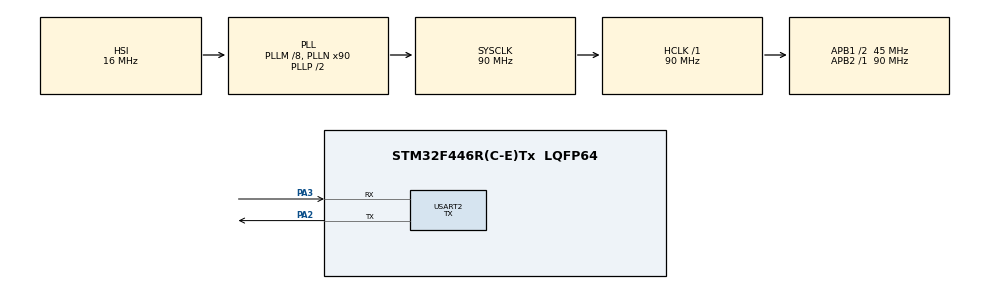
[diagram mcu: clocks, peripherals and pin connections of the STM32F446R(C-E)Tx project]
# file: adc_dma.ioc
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ADC1.Channel-0\#ChannelRegularConversion=ADC_CHANNEL_TEMPSENSOR
ADC1.ContinuousConvMode=ENABLE
ADC1.DMAContinuousRequests=DISABLE
ADC1.NbrOfConversion=1
ADC1.NbrOfConversionFlag=1
ADC1.Rank-0\#ChannelRegularConversion=1
ADC1.Resolution=ADC_RESOLUTION_8B
ADC1.SamplingTime-0\#ChannelRegularConversion=ADC_SAMPLETIME_480CYCLES
ADC1.master=1
Mcu.Family=STM32F4
Mcu.Name=STM32F446R(C-E)Tx
Mcu.Package=LQFP64
NVIC.ADC_IRQn=true\:0\:0\:false\:false\:true\:true\:true
NVIC.FPU_IRQn=true\:0\:0\:false\:false\:true\:true\:false
NVIC.PriorityGroup=NVIC_PRIORITYGROUP_4
NVIC.RCC_IRQn=true\:0\:0\:false\:false\:true\:true\:false
PA2.Mode=Asynchronous
PA2.Signal=USART2_TX
PA3.Mode=Asynchronous
PA3.Signal=USART2_RX
ProjectManager.HeapSize=0x200
ProjectManager.StackSize=0x400
ProjectManager.TargetToolchain=SW4STM32
RCC.AHBFreq_Value=90000000
RCC.APB1CLKDivider=RCC_HCLK_DIV2
RCC.APB1Freq_Value=45000000
RCC.APB1TimFreq_Value=90000000
RCC.APB2Freq_Value=90000000
RCC.APB2TimFreq_Value=90000000
RCC.CortexFreq_Value=90000000
RCC.HCLKFreq_Value=90000000
RCC.PLLM=8
RCC.PLLN=90
RCC.SYSCLKFreq_VALUE=90000000
RCC.SYSCLKSource=RCC_SYSCLKSOURCE_PLLCLK
RCC.USBFreq_Value=90000000
RCC.VCOOutputFreq_Value=180000000
USART2.Mode=MODE_TX
USART2.OverSampling=UART_OVERSAMPLING_8
USART2.VirtualMode=VM_ASYNC
VP_ADC1_TempSens_Input.Mode=IN-TempSens
board=custom

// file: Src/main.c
/* USER CODE BEGIN Header */
/**
  ******************************************************************************
  * @file           : main.c
  * @brief          : Main program body
  ******************************************************************************
  * @attention
  *
  * <h2><center>&copy; Copyright (c) 2019 STMicroelectronics.
  * All rights reserved.</center></h2>
  *
  * This software component is licensed by ST under BSD 3-Clause license,
  * the "License"; You may not use this file except in compliance with the
  * License. You may obtain a copy of the License at:
  *                        opensource.org/licenses/BSD-3-Clause
  *
  ******************************************************************************
  */
/* USER CODE END Header */

#include "main.h"

/* USER CODE BEGIN PD */

#ifdef __GNUC__
/* With GCC/RAISONANCE, small printf (option LD Linker->Libraries->Small printf
 set to 'Yes') calls __io_putchar() */
#define PUTCHAR_PROTOTYPE int __io_putchar(int ch)
#endif

/* USER CODE END PD */

ADC_HandleTypeDef hadc1;

UART_HandleTypeDef huart2;

/* USER CODE BEGIN PV */
uint16_t PomiarADC;
float Temperature;
float Vsense;

/* USER CODE END PV */

void SystemClock_Config(void);
static void MX_GPIO_Init(void);
static void MX_ADC1_Init(void);
static void MX_USART2_UART_Init(void);

/* USER CODE BEGIN 0 */
	const float V25 = 0.76; // [Volts]
	const float Avg_slope = 0.0025; //[Volts/degree]
	const float SupplyVoltage = 3.0; // [Volts]
	const float ADCResolution = 255.0;

/* USER CODE END 0 */

int main(void)
{

  /* MCU Configuration--------------------------------------------------------*/

  /* Reset of all peripherals, Initializes the Flash interface and the Systick. */
  HAL_Init();

  /* Configure the system clock */
  SystemClock_Config();

  /* Initialize all configured peripherals */
  MX_GPIO_Init();
  MX_ADC1_Init();
  MX_USART2_UART_Init();
  /* USER CODE BEGIN 2 */
  __enable_irq();
  printf("hello!\r\n");

  HAL_ADC_Start_IT(&hadc1);

  /* USER CODE END 2 */

  /* Infinite loop */
  while (1)
  {

  }
}

void SystemClock_Config(void)
{
  RCC_OscInitTypeDef RCC_OscInitStruct = {0};
  RCC_ClkInitTypeDef RCC_ClkInitStruct = {0};

  /** Configure the main internal regulator output voltage
  */
  __HAL_RCC_PWR_CLK_ENABLE();
  __HAL_PWR_VOLTAGESCALING_CONFIG(PWR_REGULATOR_VOLTAGE_SCALE3);
  /** Initializes the CPU, AHB and APB busses clocks
  */
  RCC_OscInitStruct.OscillatorType = RCC_OSCILLATORTYPE_HSI;
  RCC_OscInitStruct.HSIState = RCC_HSI_ON;
  RCC_OscInitStruct.HSICalibrationValue = RCC_HSICALIBRATION_DEFAULT;
  RCC_OscInitStruct.PLL.PLLState = RCC_PLL_ON;
  RCC_OscInitStruct.PLL.PLLSource = RCC_PLLSOURCE_HSI;
  RCC_OscInitStruct.PLL.PLLM = 8;
  RCC_OscInitStruct.PLL.PLLN = 90;
  RCC_OscInitStruct.PLL.PLLP = RCC_PLLP_DIV2;
  RCC_OscInitStruct.PLL.PLLQ = 2;
  RCC_OscInitStruct.PLL.PLLR = 2;
  if (HAL_RCC_OscConfig(&RCC_OscInitStruct) != HAL_OK)
  {
    Error_Handler();
  }
  /** Initializes the CPU, AHB and APB busses clocks
  */
  RCC_ClkInitStruct.ClockType = RCC_CLOCKTYPE_HCLK|RCC_CLOCKTYPE_SYSCLK
                              |RCC_CLOCKTYPE_PCLK1|RCC_CLOCKTYPE_PCLK2;
  RCC_ClkInitStruct.SYSCLKSource = RCC_SYSCLKSOURCE_PLLCLK;
  RCC_ClkInitStruct.AHBCLKDivider = RCC_SYSCLK_DIV1;
  RCC_ClkInitStruct.APB1CLKDivider = RCC_HCLK_DIV2;
  RCC_ClkInitStruct.APB2CLKDivider = RCC_HCLK_DIV1;

  if (HAL_RCC_ClockConfig(&RCC_ClkInitStruct, FLASH_LATENCY_2) != HAL_OK)
  {
    Error_Handler();
  }
}

static void MX_ADC1_Init(void)
{

  ADC_ChannelConfTypeDef sConfig = {0};

  /** Configure the global features of the ADC (Clock, Resolution, Data Alignment and number of conversion)
  */
  hadc1.Instance = ADC1;
  hadc1.Init.ClockPrescaler = ADC_CLOCK_SYNC_PCLK_DIV4;
  hadc1.Init.Resolution = ADC_RESOLUTION_8B;
  hadc1.Init.ScanConvMode = DISABLE;
  hadc1.Init.ContinuousConvMode = ENABLE;
  hadc1.Init.DiscontinuousConvMode = DISABLE;
  hadc1.Init.ExternalTrigConvEdge = ADC_EXTERNALTRIGCONVEDGE_NONE;
  hadc1.Init.ExternalTrigConv = ADC_SOFTWARE_START;
  hadc1.Init.DataAlign = ADC_DATAALIGN_RIGHT;
  hadc1.Init.NbrOfConversion = 1;
  hadc1.Init.DMAContinuousRequests = DISABLE;
  hadc1.Init.EOCSelection = ADC_EOC_SEQ_CONV;
  if (HAL_ADC_Init(&hadc1) != HAL_OK)
  {
    Error_Handler();
  }
  /** Configure for the selected ADC regular channel its corresponding rank in the sequencer and its sample time.
  */
  sConfig.Channel = ADC_CHANNEL_TEMPSENSOR;
  sConfig.Rank = 1;
  sConfig.SamplingTime = ADC_SAMPLETIME_480CYCLES;
  if (HAL_ADC_ConfigChannel(&hadc1, &sConfig) != HAL_OK)
  {
    Error_Handler();
  }

}

static void MX_USART2_UART_Init(void)
{

  huart2.Instance = USART2;
  huart2.Init.BaudRate = 115200;
  huart2.Init.WordLength = UART_WORDLENGTH_8B;
  huart2.Init.StopBits = UART_STOPBITS_1;
  huart2.Init.Parity = UART_PARITY_NONE;
  huart2.Init.Mode = UART_MODE_TX;
  huart2.Init.HwFlowCtl = UART_HWCONTROL_NONE;
  huart2.Init.OverSampling = UART_OVERSAMPLING_8;
  if (HAL_UART_Init(&huart2) != HAL_OK)
  {
    Error_Handler();
  }

}

static void MX_GPIO_Init(void)
{

  /* GPIO Ports Clock Enable */
  __HAL_RCC_GPIOA_CLK_ENABLE();

}

/* USER CODE BEGIN 4 */
PUTCHAR_PROTOTYPE
{
 /* Place your implementation of fputc here */
 /* e.g. write a character to the USART2 and Loop until the end of transmission */
 HAL_UART_Transmit(&huart2, (uint8_t *)&ch, 1, 0xFFFF);

return ch;
}

void HAL_ADC_ConvCpltCallback(ADC_HandleTypeDef* hadc){
 PomiarADC = HAL_ADC_GetValue(&hadc1); // Pobranie zmierzonej wartosci
 Vsense = (SupplyVoltage*PomiarADC)/(ADCResolution-1); // Przeliczenie wartosci zmierzonej na napiecie
 Temperature = ((Vsense-V25)/Avg_slope)+25; // Obliczenie temperatury

 printf("Meas: %d == %4.6f == %4.6f\r\n", PomiarADC, Vsense, Temperature);
}
/* USER CODE END 4 */

void Error_Handler(void)
{
}

/************************ (C) COPYRIGHT STMicroelectronics *****END OF FILE****/
